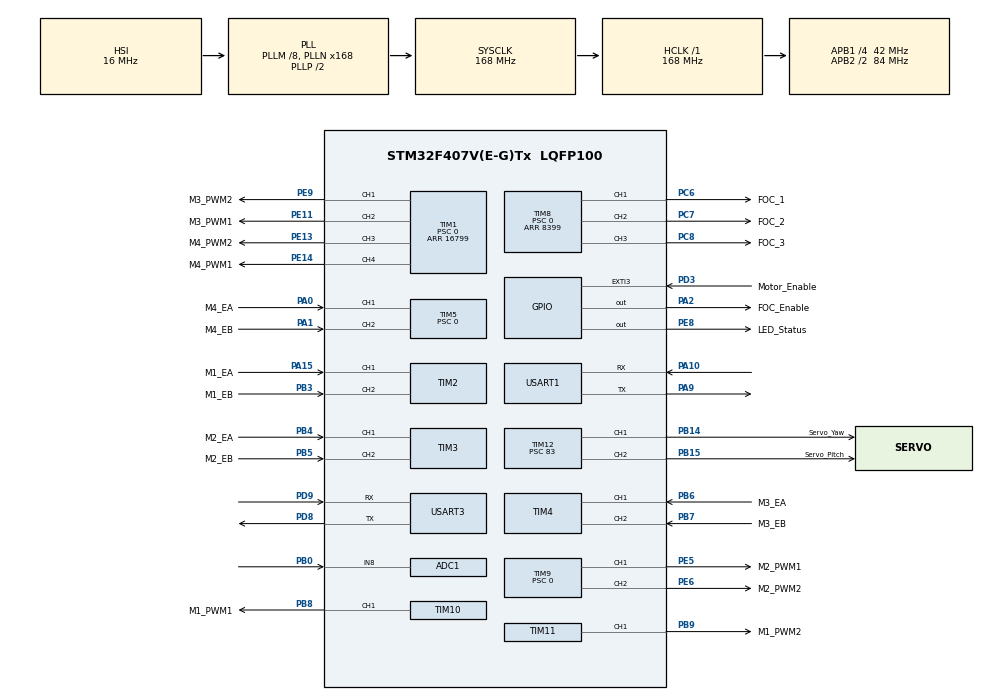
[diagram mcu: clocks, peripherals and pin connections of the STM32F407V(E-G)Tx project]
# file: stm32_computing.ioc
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ADC1.Channel-0\#ChannelRegularConversion=ADC_CHANNEL_8
ADC1.ClockPrescaler=ADC_CLOCK_SYNC_PCLK_DIV6
ADC1.NbrOfConversionFlag=1
ADC1.Rank-0\#ChannelRegularConversion=1
ADC1.SamplingTime-0\#ChannelRegularConversion=ADC_SAMPLETIME_3CYCLES
ADC1.master=1
Dma.Request0=USART1_RX
Dma.Request1=USART1_TX
Dma.USART1_RX.0.Direction=DMA_PERIPH_TO_MEMORY
Dma.USART1_RX.0.FIFOMode=DMA_FIFOMODE_DISABLE
Dma.USART1_RX.0.Instance=DMA2_Stream2
Dma.USART1_RX.0.MemDataAlignment=DMA_MDATAALIGN_BYTE
Dma.USART1_RX.0.MemInc=DMA_MINC_ENABLE
Dma.USART1_RX.0.Mode=DMA_NORMAL
Dma.USART1_RX.0.PeriphDataAlignment=DMA_PDATAALIGN_BYTE
Dma.USART1_RX.0.PeriphInc=DMA_PINC_DISABLE
Dma.USART1_RX.0.Priority=DMA_PRIORITY_LOW
Dma.USART1_TX.1.Direction=DMA_MEMORY_TO_PERIPH
Dma.USART1_TX.1.FIFOMode=DMA_FIFOMODE_DISABLE
Dma.USART1_TX.1.Instance=DMA2_Stream7
Dma.USART1_TX.1.MemDataAlignment=DMA_MDATAALIGN_BYTE
Dma.USART1_TX.1.MemInc=DMA_MINC_ENABLE
Dma.USART1_TX.1.Mode=DMA_NORMAL
Dma.USART1_TX.1.PeriphDataAlignment=DMA_PDATAALIGN_BYTE
Dma.USART1_TX.1.PeriphInc=DMA_PINC_DISABLE
Dma.USART1_TX.1.Priority=DMA_PRIORITY_LOW
Mcu.Family=STM32F4
Mcu.Name=STM32F407V(E-G)Tx
Mcu.Package=LQFP100
NVIC.DMA2_Stream2_IRQn=true\:0\:0\:false\:false\:true\:false\:true\:true
NVIC.DMA2_Stream7_IRQn=true\:0\:0\:false\:false\:true\:false\:true\:true
NVIC.EXTI3_IRQn=true\:0\:0\:false\:false\:true\:true\:true\:true
NVIC.PriorityGroup=NVIC_PRIORITYGROUP_4
NVIC.TIM6_DAC_IRQn=true\:0\:0\:false\:false\:true\:true\:true\:true
NVIC.TIM8_UP_TIM13_IRQn=true\:0\:0\:false\:false\:true\:true\:true\:true
NVIC.USART1_IRQn=true\:0\:0\:false\:false\:true\:true\:true\:true
NVIC.USART3_IRQn=true\:0\:0\:false\:false\:true\:true\:true\:true
PA0-WKUP.GPIO_Label=M4_EA
PA0-WKUP.GPIO_PuPd=GPIO_PULLUP
PA0-WKUP.Signal=S_TIM5_CH1
PA1.GPIO_Label=M4_EB
PA1.GPIO_PuPd=GPIO_PULLUP
PA1.Signal=S_TIM5_CH2
PA10.Mode=Asynchronous
PA10.Signal=USART1_RX
PA13.Mode=Serial_Wire
PA13.Signal=SYS_JTMS-SWDIO
PA14.Mode=Serial_Wire
PA14.Signal=SYS_JTCK-SWCLK
PA15.GPIO_Label=M1_EA
PA15.GPIO_ModeDefaultPP=GPIO_MODE_AF_PP
PA15.GPIO_PuPd=GPIO_PULLUP
PA15.Signal=S_TIM2_CH1_ETR
PA2.GPIO_Label=FOC_Enable
PA2.GPIO_Speed=GPIO_SPEED_FREQ_VERY_HIGH
PA2.Signal=GPIO_Output
PA9.Mode=Asynchronous
PA9.Signal=USART1_TX
PB0.Signal=ADCx_IN8
PB14.GPIO_Label=Servo_Yaw
PB14.Signal=S_TIM12_CH1
PB15.GPIO_Label=Servo_Pitch
PB15.Signal=S_TIM12_CH2
PB3.GPIO_Label=M1_EB
PB3.GPIO_PuPd=GPIO_PULLUP
PB3.Signal=S_TIM2_CH2
PB4.GPIO_Label=M2_EA
PB4.GPIO_PuPd=GPIO_PULLUP
PB4.Signal=S_TIM3_CH1
PB5.GPIO_Label=M2_EB
PB5.GPIO_PuPd=GPIO_PULLUP
PB5.Signal=S_TIM3_CH2
PB6.GPIO_Label=M3_EA
PB6.GPIO_PuPd=GPIO_PULLUP
PB6.Signal=S_TIM4_CH1
PB7.GPIO_Label=M3_EB
PB7.GPIO_PuPd=GPIO_PULLUP
PB7.Signal=S_TIM4_CH2
PB8.GPIO_Label=M1_PWM1
PB8.GPIO_Speed=GPIO_SPEED_FREQ_HIGH
PB8.Signal=S_TIM10_CH1
PB9.GPIO_Label=M1_PWM2
PB9.GPIO_Speed=GPIO_SPEED_FREQ_HIGH
PB9.Signal=S_TIM11_CH1
PC6.GPIO_Label=FOC_1
PC6.Signal=S_TIM8_CH1
PC7.GPIO_Label=FOC_2
PC7.Signal=S_TIM8_CH2
PC8.GPIO_Label=FOC_3
PC8.Signal=S_TIM8_CH3
PD3.GPIO_Label=Motor_Enable
PD3.GPIO_ModeDefaultEXTI=GPIO_MODE_IT_RISING_FALLING
PD3.Signal=GPXTI3
PD8.Mode=Asynchronous
PD8.Signal=USART3_TX
PD9.Mode=Asynchronous
PD9.Signal=USART3_RX
PE11.GPIO_Label=M3_PWM1
PE11.GPIO_Speed=GPIO_SPEED_FREQ_HIGH
PE11.Signal=S_TIM1_CH2
PE13.GPIO_Label=M4_PWM2
PE13.GPIO_Speed=GPIO_SPEED_FREQ_HIGH
PE13.Signal=S_TIM1_CH3
PE14.GPIO_Label=M4_PWM1
PE14.GPIO_Speed=GPIO_SPEED_FREQ_HIGH
PE14.Signal=S_TIM1_CH4
PE5.GPIO_Label=M2_PWM1
PE5.GPIO_Speed=GPIO_SPEED_FREQ_HIGH
PE5.Signal=S_TIM9_CH1
PE6.GPIO_Label=M2_PWM2
PE6.GPIO_Speed=GPIO_SPEED_FREQ_HIGH
PE6.Signal=S_TIM9_CH2
PE8.GPIO_Label=LED_Status
PE8.GPIO_Speed=GPIO_SPEED_FREQ_VERY_HIGH
PE8.PinState=GPIO_PIN_RESET
PE8.Signal=GPIO_Output
PE9.GPIO_Label=M3_PWM2
PE9.GPIO_Speed=GPIO_SPEED_FREQ_HIGH
PE9.Signal=S_TIM1_CH1
PH0-OSC_IN.Mode=HSE-External-Oscillator
PH0-OSC_IN.Signal=RCC_OSC_IN
PH1-OSC_OUT.Mode=HSE-External-Oscillator
PH1-OSC_OUT.Signal=RCC_OSC_OUT
ProjectManager.HeapSize=0x200
ProjectManager.StackSize=0x400
ProjectManager.TargetToolchain=MDK-ARM V5.32
RCC.48MHZClocksFreq_Value=84000000
RCC.AHBFreq_Value=168000000
RCC.APB1CLKDivider=RCC_HCLK_DIV4
RCC.APB1Freq_Value=42000000
RCC.APB1TimFreq_Value=84000000
RCC.APB2CLKDivider=RCC_HCLK_DIV2
RCC.APB2Freq_Value=84000000
RCC.APB2TimFreq_Value=168000000
RCC.CortexFreq_Value=168000000
RCC.HCLKFreq_Value=168000000
RCC.HSE_VALUE=25000000
RCC.HSI_VALUE=16000000
RCC.LSE_VALUE=32768
RCC.PLLM=8
RCC.PLLN=168
RCC.SYSCLKFreq_VALUE=168000000
RCC.SYSCLKSource=RCC_SYSCLKSOURCE_PLLCLK
RCC.VCOOutputFreq_Value=336000000
SH.ADCx_IN8.0=ADC1_IN8,IN8
SH.S_TIM10_CH1.0=TIM10_CH1,PWM Generation1 CH1
SH.S_TIM11_CH1.0=TIM11_CH1,PWM Generation1 CH1
SH.S_TIM12_CH1.0=TIM12_CH1,PWM Generation1 CH1
SH.S_TIM12_CH2.0=TIM12_CH2,PWM Generation2 CH2
SH.S_TIM1_CH1.0=TIM1_CH1,PWM Generation1 CH1
SH.S_TIM1_CH2.0=TIM1_CH2,PWM Generation2 CH2
SH.S_TIM1_CH3.0=TIM1_CH3,PWM Generation3 CH3
SH.S_TIM1_CH4.0=TIM1_CH4,PWM Generation4 CH4
SH.S_TIM2_CH1_ETR.0=TIM2_CH1,Encoder_Interface
SH.S_TIM2_CH2.0=TIM2_CH2,Encoder_Interface
SH.S_TIM3_CH1.0=TIM3_CH1,Encoder_Interface
SH.S_TIM3_CH2.0=TIM3_CH2,Encoder_Interface
SH.S_TIM4_CH1.0=TIM4_CH1,Encoder_Interface
SH.S_TIM4_CH2.0=TIM4_CH2,Encoder_Interface
SH.S_TIM5_CH1.0=TIM5_CH1,Encoder_Interface
SH.S_TIM5_CH2.0=TIM5_CH2,Encoder_Interface
SH.S_TIM8_CH1.0=TIM8_CH1,PWM Generation1 CH1
SH.S_TIM8_CH2.0=TIM8_CH2,PWM Generation2 CH2
SH.S_TIM8_CH3.0=TIM8_CH3,PWM Generation3 CH3
SH.S_TIM9_CH1.0=TIM9_CH1,PWM Generation1 CH1
SH.S_TIM9_CH2.0=TIM9_CH2,PWM Generation2 CH2
TIM1.AutoReloadPreload=TIM_AUTORELOAD_PRELOAD_ENABLE
TIM1.Channel-PWM\ Generation1\ CH1=TIM_CHANNEL_1
TIM1.Channel-PWM\ Generation2\ CH2=TIM_CHANNEL_2
TIM1.Channel-PWM\ Generation3\ CH3=TIM_CHANNEL_3
TIM1.Channel-PWM\ Generation4\ CH4=TIM_CHANNEL_4
TIM1.Period=16799
TIM1.Prescaler=0
TIM1.Pulse-PWM\ Generation1\ CH1=16799
TIM1.Pulse-PWM\ Generation2\ CH2=16799
TIM1.Pulse-PWM\ Generation3\ CH3=16799
TIM1.Pulse-PWM\ Generation4\ CH4=16799
TIM10.AutoReloadPreload=TIM_AUTORELOAD_PRELOAD_ENABLE
TIM10.Channel=TIM_CHANNEL_1
TIM10.Period=16799
TIM10.Prescaler=0
TIM10.Pulse=16799
TIM11.AutoReloadPreload=TIM_AUTORELOAD_PRELOAD_ENABLE
TIM11.Channel=TIM_CHANNEL_1
TIM11.Period=16799
TIM11.Prescaler=0
TIM11.Pulse=16799
TIM12.Channel-PWM\ Generation1\ CH1=TIM_CHANNEL_1
TIM12.Channel-PWM\ Generation2\ CH2=TIM_CHANNEL_2
TIM12.Period=9999
TIM12.Prescaler=83
TIM12.Pulse-PWM\ Generation1\ CH1=1500
TIM12.Pulse-PWM\ Generation2\ CH2=1500
TIM13.Period=99
TIM13.Prescaler=8399
TIM2.AutoReloadPreload=TIM_AUTORELOAD_PRELOAD_ENABLE
TIM2.EncoderMode=TIM_ENCODERMODE_TI12
TIM3.AutoReloadPreload=TIM_AUTORELOAD_PRELOAD_ENABLE
TIM3.EncoderMode=TIM_ENCODERMODE_TI12
TIM4.AutoReloadPreload=TIM_AUTORELOAD_PRELOAD_ENABLE
TIM4.EncoderMode=TIM_ENCODERMODE_TI12
TIM5.AutoReloadPreload=TIM_AUTORELOAD_PRELOAD_ENABLE
TIM5.EncoderMode=TIM_ENCODERMODE_TI12
TIM5.Prescaler=0
TIM6.Period=16799
TIM8.BreakState=TIM_BREAK_DISABLE
TIM8.Channel-PWM\ Generation1\ CH1=TIM_CHANNEL_1
TIM8.Channel-PWM\ Generation2\ CH2=TIM_CHANNEL_2
TIM8.Channel-PWM\ Generation3\ CH3=TIM_CHANNEL_3
TIM8.CounterMode=TIM_COUNTERMODE_CENTERALIGNED1
TIM8.Period=8399
TIM8.Prescaler=0
TIM8.Pulse-PWM\ Generation2\ CH2=0
TIM8.Pulse-PWM\ Generation3\ CH3=0
TIM9.AutoReloadPreload=TIM_AUTORELOAD_PRELOAD_ENABLE
TIM9.Channel-PWM\ Generation1\ CH1=TIM_CHANNEL_1
TIM9.Channel-PWM\ Generation2\ CH2=TIM_CHANNEL_2
TIM9.Period=16799
TIM9.Prescaler=0
TIM9.Pulse-PWM\ Generation1\ CH1=16799
TIM9.Pulse-PWM\ Generation2\ CH2=16799
USART1.VirtualMode=VM_ASYNC
USART3.VirtualMode=VM_ASYNC
VP_TIM10_VS_ClockSourceINT.Mode=Enable_Timer
VP_TIM11_VS_ClockSourceINT.Mode=Enable_Timer
VP_TIM13_VS_ClockSourceINT.Mode=Enable_Timer
VP_TIM6_VS_ClockSourceINT.Mode=Enable_Timer
VP_TIM8_VS_ClockSourceINT.Mode=Internal
board=custom

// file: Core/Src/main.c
/* USER CODE BEGIN Header */
/**
  ******************************************************************************
  * @file           : main.c
  * @brief          : Main program body
  ******************************************************************************
  * @attention
  *
  * Copyright (c) 2026 STMicroelectronics.
  * All rights reserved.
  *
  * This software is licensed under terms that can be found in the LICENSE file
  * in the root directory of this software component.
  * If no LICENSE file comes with this software, it is provided AS-IS.
  *
  ******************************************************************************
  */
/* USER CODE END Header */
#include "main.h"
#include "adc.h"
#include "dma.h"
#include "tim.h"
#include "usart.h"
#include "gpio.h"

/* USER CODE BEGIN Includes */
#include "Motor.h"
#include "bsp_oled.h"
/* USER CODE END Includes */

/* USER CODE BEGIN PV */
uint8_t UsartTempRxBuffer[2]={0x00,0x01};
/* USER CODE END PV */

void SystemClock_Config(void);

int main(void)
{

  /* MCU Configuration--------------------------------------------------------*/

  /* Reset of all peripherals, Initializes the Flash interface and the Systick. */
  HAL_Init();

  /* Configure the system clock */
  SystemClock_Config();

  /* Initialize all configured peripherals */
  MX_GPIO_Init();
  MX_DMA_Init();
  MX_TIM1_Init();
  MX_TIM2_Init();
  MX_TIM3_Init();
  MX_TIM4_Init();
  MX_TIM5_Init();
  MX_TIM9_Init();
  MX_TIM10_Init();
  MX_TIM11_Init();
  MX_USART3_UART_Init();
  MX_ADC1_Init();
  MX_TIM13_Init();
  MX_USART1_UART_Init();
  MX_TIM8_Init();
  MX_TIM6_Init();
  MX_TIM12_Init();
  /* USER CODE BEGIN 2 */
	OLED_Init();
	HAL_TIM_Encoder_Start(&htim2,TIM_CHANNEL_ALL);

	HAL_TIM_PWM_Start(&htim10, TIM_CHANNEL_1);
	HAL_TIM_PWM_Start(&htim11, TIM_CHANNEL_1);

	HAL_UART_Receive_IT(&huart3, UsartTempRxBuffer, 2);
  /* USER CODE END 2 */

  /* Infinite loop */
  while (1)
  {

  }
}

void SystemClock_Config(void)
{
  RCC_OscInitTypeDef RCC_OscInitStruct = {0};
  RCC_ClkInitTypeDef RCC_ClkInitStruct = {0};

  /** Configure the main internal regulator output voltage
  */
  __HAL_RCC_PWR_CLK_ENABLE();
  __HAL_PWR_VOLTAGESCALING_CONFIG(PWR_REGULATOR_VOLTAGE_SCALE1);

  /** Initializes the RCC Oscillators according to the specified parameters
  * in the RCC_OscInitTypeDef structure.
  */
  RCC_OscInitStruct.OscillatorType = RCC_OSCILLATORTYPE_HSI;
  RCC_OscInitStruct.HSIState = RCC_HSI_ON;
  RCC_OscInitStruct.HSICalibrationValue = RCC_HSICALIBRATION_DEFAULT;
  RCC_OscInitStruct.PLL.PLLState = RCC_PLL_ON;
  RCC_OscInitStruct.PLL.PLLSource = RCC_PLLSOURCE_HSI;
  RCC_OscInitStruct.PLL.PLLM = 8;
  RCC_OscInitStruct.PLL.PLLN = 168;
  RCC_OscInitStruct.PLL.PLLP = RCC_PLLP_DIV2;
  RCC_OscInitStruct.PLL.PLLQ = 4;
  if (HAL_RCC_OscConfig(&RCC_OscInitStruct) != HAL_OK)
  {
    Error_Handler();
  }

  /** Initializes the CPU, AHB and APB buses clocks
  */
  RCC_ClkInitStruct.ClockType = RCC_CLOCKTYPE_HCLK|RCC_CLOCKTYPE_SYSCLK
                              |RCC_CLOCKTYPE_PCLK1|RCC_CLOCKTYPE_PCLK2;
  RCC_ClkInitStruct.SYSCLKSource = RCC_SYSCLKSOURCE_PLLCLK;
  RCC_ClkInitStruct.AHBCLKDivider = RCC_SYSCLK_DIV1;
  RCC_ClkInitStruct.APB1CLKDivider = RCC_HCLK_DIV4;
  RCC_ClkInitStruct.APB2CLKDivider = RCC_HCLK_DIV2;

  if (HAL_RCC_ClockConfig(&RCC_ClkInitStruct, FLASH_LATENCY_5) != HAL_OK)
  {
    Error_Handler();
  }
}

/* USER CODE BEGIN 4 */
void HAL_UART_RxCpltCallback(UART_HandleTypeDef *huart) {
    if (huart == &huart3)
	{
		Motor_PWM_DR_Control(MotorA,UsartTempRxBuffer[0],(bool)UsartTempRxBuffer[1]);
        HAL_UART_Receive_IT(&huart3, UsartTempRxBuffer, 1);
    }
}
/* USER CODE END 4 */

void Error_Handler(void)
{
  __disable_irq();
  while (1)
  {
  }
}
